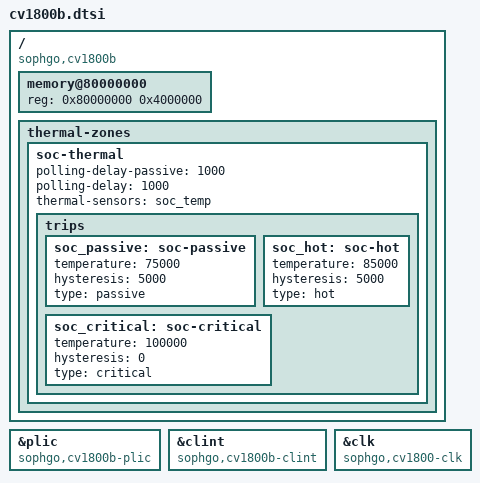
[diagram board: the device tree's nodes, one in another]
// SPDX-License-Identifier: (GPL-2.0 OR MIT)
/*
 * Copyright (C) 2023 Jisheng Zhang <jszhang@kernel.org>
 */

#include "cv18xx.dtsi"

/ {
	compatible = "sophgo,cv1800b";

	memory@80000000 {
		device_type = "memory";
		reg = <0x80000000 0x4000000>;
	};

	thermal-zones {
		soc-thermal {
			polling-delay-passive   = <1000>;
			polling-delay           = <1000>;
			thermal-sensors         = <&soc_temp>;

			trips {
				soc_passive: soc-passive {
					temperature     = <75000>;
					hysteresis      = <5000>;
					type            = "passive";
				};

				soc_hot: soc-hot {
					temperature     = <85000>;
					hysteresis      = <5000>;
					type            = "hot";
				};

				soc_critical: soc-critical {
					temperature     = <100000>;
					hysteresis      = <0>;
					type            = "critical";
				};
			};
		};
	};
};

&plic {
	compatible = "sophgo,cv1800b-plic", "thead,c900-plic";
};

&clint {
	compatible = "sophgo,cv1800b-clint", "thead,c900-clint";
};

&clk {
	compatible = "sophgo,cv1800-clk";
};
